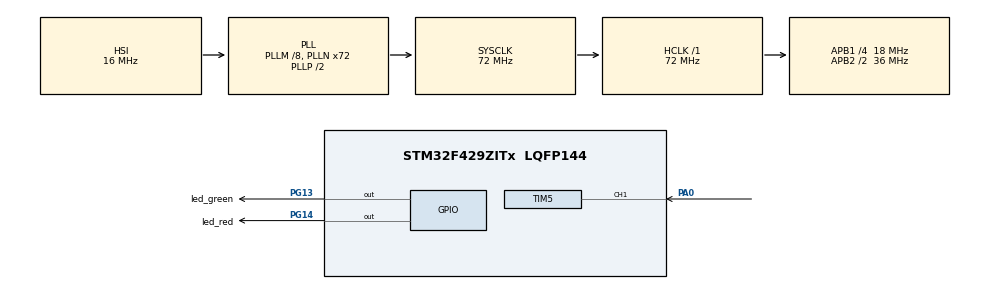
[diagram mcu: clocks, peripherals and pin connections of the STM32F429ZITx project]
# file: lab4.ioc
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Mcu.Family=STM32F4
Mcu.Name=STM32F429ZITx
Mcu.Package=LQFP144
NVIC.PriorityGroup=NVIC_PRIORITYGROUP_4
NVIC.TIM4_IRQn=true\:0\:0\:false\:true\:true\:2\:true\:true\:true
NVIC.TIM5_IRQn=true\:0\:0\:false\:true\:true\:1\:true\:true\:true
PA0/WKUP.Signal=S_TIM5_CH1
PG13.GPIO_Label=led_green
PG13.Signal=GPIO_Output
PG14.GPIO_Label=led_red
PG14.Signal=GPIO_Output
ProjectManager.HeapSize=0x200
ProjectManager.StackSize=0x400
ProjectManager.TargetToolchain=STM32CubeIDE
RCC.48MHZClocksFreq_Value=48000000
RCC.AHBFreq_Value=72000000
RCC.APB1CLKDivider=RCC_HCLK_DIV4
RCC.APB1Freq_Value=18000000
RCC.APB1TimFreq_Value=36000000
RCC.APB2CLKDivider=RCC_HCLK_DIV2
RCC.APB2Freq_Value=36000000
RCC.APB2TimFreq_Value=72000000
RCC.CortexFreq_Value=72000000
RCC.HCLKFreq_Value=72000000
RCC.HSE_VALUE=8000000
RCC.HSI_VALUE=16000000
RCC.LSE_VALUE=32768
RCC.PLLM=8
RCC.PLLN=72
RCC.PLLQ=3
RCC.PLLSAIN=50
RCC.SYSCLKFreq_VALUE=72000000
RCC.SYSCLKSource=RCC_SYSCLKSOURCE_PLLCLK
RCC.VCOOutputFreq_Value=144000000
SH.S_TIM5_CH1.0=TIM5_CH1,Input_Capture1_from_TI1
TIM4.Period=500-1
TIM4.Prescaler=36000-1
TIM5.Channel-Input_Capture1_from_TI1=TIM_CHANNEL_1
TIM5.Prescaler=3600
VP_TIM4_VS_ClockSourceINT.Mode=Internal
board=STM32F429I-DISC1

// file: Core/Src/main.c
/* USER CODE BEGIN Header */
/**
  ******************************************************************************
  * @file           : main.c
  * @brief          : Main program body
  ******************************************************************************
  * @attention
  *
  * Copyright (c) 2026 STMicroelectronics.
  * All rights reserved.
  *
  * This software is licensed under terms that can be found in the LICENSE file
  * in the root directory of this software component.
  * If no LICENSE file comes with this software, it is provided AS-IS.
  *
  ******************************************************************************
  */
/* USER CODE END Header */
#include "main.h"

TIM_HandleTypeDef htim4;
TIM_HandleTypeDef htim5;

/* USER CODE BEGIN PV */
int task = 3;
uint8_t timer_ticks = 0;

uint32_t IC_Value1 = 0;
uint32_t IC_Value2 = 0;
uint32_t Difference = 0;
float Time_Seconds = 0;
uint8_t Capture_Count = 0;
/* USER CODE END PV */

void SystemClock_Config(void);
static void MX_GPIO_Init(void);
static void MX_TIM4_Init(void);
static void MX_TIM5_Init(void);
static void MX_NVIC_Init(void);

int main(void)
{

  /* MCU Configuration--------------------------------------------------------*/

  /* Reset of all peripherals, Initializes the Flash interface and the Systick. */
  HAL_Init();

  /* Configure the system clock */
  SystemClock_Config();

  /* Initialize all configured peripherals */
  MX_GPIO_Init();
  MX_TIM4_Init();
  MX_TIM5_Init();

  /* Initialize interrupts */
  MX_NVIC_Init();
  /* USER CODE BEGIN 2 */
  HAL_TIM_Base_Start_IT(&htim4);
  HAL_TIM_IC_Start_IT(&htim5, TIM_CHANNEL_1);
  /* USER CODE END 2 */

  /* Infinite loop */
  /* USER CODE BEGIN WHILE */
  while (1)
  {
	  if (task == 2 && Capture_Count == 1) { // Jei matavimas vyksta (paspaustas pirmą kartą)
	          HAL_GPIO_WritePin(GPIOG, GPIO_PIN_13 | GPIO_PIN_14, GPIO_PIN_SET);
	          HAL_Delay(100); // Trumpas mirktelėjimas
	          HAL_GPIO_WritePin(GPIOG, GPIO_PIN_13 | GPIO_PIN_14, GPIO_PIN_RESET);
	          HAL_Delay(1900); // Likusi dalis iki 2 sekundžių
	      }
    /* USER CODE END WHILE */

  }
}

void SystemClock_Config(void)
{
  RCC_OscInitTypeDef RCC_OscInitStruct = {0};
  RCC_ClkInitTypeDef RCC_ClkInitStruct = {0};

  /** Configure the main internal regulator output voltage
  */
  __HAL_RCC_PWR_CLK_ENABLE();
  __HAL_PWR_VOLTAGESCALING_CONFIG(PWR_REGULATOR_VOLTAGE_SCALE3);

  /** Initializes the RCC Oscillators according to the specified parameters
  * in the RCC_OscInitTypeDef structure.
  */
  RCC_OscInitStruct.OscillatorType = RCC_OSCILLATORTYPE_HSI;
  RCC_OscInitStruct.HSIState = RCC_HSI_ON;
  RCC_OscInitStruct.HSICalibrationValue = RCC_HSICALIBRATION_DEFAULT;
  RCC_OscInitStruct.PLL.PLLState = RCC_PLL_ON;
  RCC_OscInitStruct.PLL.PLLSource = RCC_PLLSOURCE_HSI;
  RCC_OscInitStruct.PLL.PLLM = 8;
  RCC_OscInitStruct.PLL.PLLN = 72;
  RCC_OscInitStruct.PLL.PLLP = RCC_PLLP_DIV2;
  RCC_OscInitStruct.PLL.PLLQ = 3;
  if (HAL_RCC_OscConfig(&RCC_OscInitStruct) != HAL_OK)
  {
    Error_Handler();
  }

  /** Initializes the CPU, AHB and APB buses clocks
  */
  RCC_ClkInitStruct.ClockType = RCC_CLOCKTYPE_HCLK|RCC_CLOCKTYPE_SYSCLK
                              |RCC_CLOCKTYPE_PCLK1|RCC_CLOCKTYPE_PCLK2;
  RCC_ClkInitStruct.SYSCLKSource = RCC_SYSCLKSOURCE_PLLCLK;
  RCC_ClkInitStruct.AHBCLKDivider = RCC_SYSCLK_DIV1;
  RCC_ClkInitStruct.APB1CLKDivider = RCC_HCLK_DIV4;
  RCC_ClkInitStruct.APB2CLKDivider = RCC_HCLK_DIV2;

  if (HAL_RCC_ClockConfig(&RCC_ClkInitStruct, FLASH_LATENCY_2) != HAL_OK)
  {
    Error_Handler();
  }
}

/**
  * @brief NVIC Configuration.
  * @retval None
  */
static void MX_NVIC_Init(void)
{
  /* TIM5_IRQn interrupt configuration */
  HAL_NVIC_SetPriority(TIM5_IRQn, 0, 0);
  HAL_NVIC_EnableIRQ(TIM5_IRQn);
  /* TIM4_IRQn interrupt configuration */
  HAL_NVIC_SetPriority(TIM4_IRQn, 0, 0);
  HAL_NVIC_EnableIRQ(TIM4_IRQn);
}

static void MX_TIM4_Init(void)
{

  TIM_ClockConfigTypeDef sClockSourceConfig = {0};
  TIM_MasterConfigTypeDef sMasterConfig = {0};

  htim4.Instance = TIM4;
  htim4.Init.Prescaler = 36000-1;
  htim4.Init.CounterMode = TIM_COUNTERMODE_UP;
  htim4.Init.Period = 500-1;
  htim4.Init.ClockDivision = TIM_CLOCKDIVISION_DIV1;
  htim4.Init.AutoReloadPreload = TIM_AUTORELOAD_PRELOAD_DISABLE;
  if (HAL_TIM_Base_Init(&htim4) != HAL_OK)
  {
    Error_Handler();
  }
  sClockSourceConfig.ClockSource = TIM_CLOCKSOURCE_INTERNAL;
  if (HAL_TIM_ConfigClockSource(&htim4, &sClockSourceConfig) != HAL_OK)
  {
    Error_Handler();
  }
  sMasterConfig.MasterOutputTrigger = TIM_TRGO_RESET;
  sMasterConfig.MasterSlaveMode = TIM_MASTERSLAVEMODE_DISABLE;
  if (HAL_TIMEx_MasterConfigSynchronization(&htim4, &sMasterConfig) != HAL_OK)
  {
    Error_Handler();
  }

}

static void MX_TIM5_Init(void)
{

  TIM_MasterConfigTypeDef sMasterConfig = {0};
  TIM_IC_InitTypeDef sConfigIC = {0};

  htim5.Instance = TIM5;
  htim5.Init.Prescaler = 3600;
  htim5.Init.CounterMode = TIM_COUNTERMODE_UP;
  htim5.Init.Period = 4294967295;
  htim5.Init.ClockDivision = TIM_CLOCKDIVISION_DIV1;
  htim5.Init.AutoReloadPreload = TIM_AUTORELOAD_PRELOAD_DISABLE;
  if (HAL_TIM_IC_Init(&htim5) != HAL_OK)
  {
    Error_Handler();
  }
  sMasterConfig.MasterOutputTrigger = TIM_TRGO_RESET;
  sMasterConfig.MasterSlaveMode = TIM_MASTERSLAVEMODE_DISABLE;
  if (HAL_TIMEx_MasterConfigSynchronization(&htim5, &sMasterConfig) != HAL_OK)
  {
    Error_Handler();
  }
  sConfigIC.ICPolarity = TIM_INPUTCHANNELPOLARITY_RISING;
  sConfigIC.ICSelection = TIM_ICSELECTION_DIRECTTI;
  sConfigIC.ICPrescaler = TIM_ICPSC_DIV1;
  sConfigIC.ICFilter = 0;
  if (HAL_TIM_IC_ConfigChannel(&htim5, &sConfigIC, TIM_CHANNEL_1) != HAL_OK)
  {
    Error_Handler();
  }

}

static void MX_GPIO_Init(void)
{
  GPIO_InitTypeDef GPIO_InitStruct = {0};

  /* GPIO Ports Clock Enable */
  __HAL_RCC_GPIOA_CLK_ENABLE();
  __HAL_RCC_GPIOG_CLK_ENABLE();

  /*Configure GPIO pin Output Level */
  HAL_GPIO_WritePin(GPIOG, led_green_Pin|led_red_Pin, GPIO_PIN_RESET);

  /*Configure GPIO pins : led_green_Pin led_red_Pin */
  GPIO_InitStruct.Pin = led_green_Pin|led_red_Pin;
  GPIO_InitStruct.Mode = GPIO_MODE_OUTPUT_PP;
  GPIO_InitStruct.Pull = GPIO_NOPULL;
  GPIO_InitStruct.Speed = GPIO_SPEED_FREQ_LOW;
  HAL_GPIO_Init(GPIOG, &GPIO_InitStruct);

}

/* USER CODE BEGIN 4 */

void HAL_TIM_PeriodElapsedCallback(TIM_HandleTypeDef *htim) {
    if (task == 1 && htim->Instance == TIM4) {
        // Didiname žingsnių skaitiklį (nuo 0 iki 3, viso 4 žingsniai po 0.5s)
        timer_ticks++;
        if (timer_ticks >= 4) {
            timer_ticks = 0;
        }

        // --- PG13 VALDYMAS (Kinta kas 1 sekundę) ---
        // Kadangi pertrauktis kas 0.5s, būseną keičiame kas antrą pertrauktį
        if (timer_ticks % 2 == 0) {
            HAL_GPIO_TogglePin(GPIOG, GPIO_PIN_13);
        }

        // --- PG14 VALDYMAS (2s periodas: 1.5s ON, 0.5s OFF) ---
        // Žingsniai: 0 (0.5s), 1 (1.0s), 2 (1.5s) -> ON; 3 (2.0s) -> OFF
        if (timer_ticks < 3) {
            HAL_GPIO_WritePin(GPIOG, GPIO_PIN_14, GPIO_PIN_SET);   // Įjungtas
        } else {
            HAL_GPIO_WritePin(GPIOG, GPIO_PIN_14, GPIO_PIN_RESET); // Išjungtas
        }
    }
}

void HAL_TIM_IC_CaptureCallback(TIM_HandleTypeDef *htim) {
    if (task==2 && htim->Instance == TIM5) {
        if (Capture_Count == 0) { // Pirmas paspaudimas
            IC_Value1 = HAL_TIM_ReadCapturedValue(htim, TIM_CHANNEL_1);
            Capture_Count = 1;

            // Išjungiame visus LED prieš naują matavimą
            HAL_GPIO_WritePin(GPIOG, GPIO_PIN_13 | GPIO_PIN_14, GPIO_PIN_RESET);

        } else if (Capture_Count == 1) { // Antras paspaudimas
            IC_Value2 = HAL_TIM_ReadCapturedValue(htim, TIM_CHANNEL_1);

            // Skaičiuojame skirtumą (įvertinant galimą laikmačio persipildymą)
            if (IC_Value2 > IC_Value1) {
                Difference = IC_Value2 - IC_Value1;
            } else {
                Difference = (0xFFFFFFFF - IC_Value1) + IC_Value2;
            }

            // Paverčiame į sekundes (jei dažnis 10kHz, dalijame iš 10000)
            Time_Seconds = (float)Difference / 10000.0f;

            // REZULTATO INDIKACIJA pagal lentelę (pavyzdys):
            if (Time_Seconds > 0 && Time_Seconds <= 2.0) {
                HAL_GPIO_WritePin(GPIOG, GPIO_PIN_13, GPIO_PIN_SET); // Pvz. tik vienas LED
            } else if (Time_Seconds > 2.0 && Time_Seconds <= 4.0) {
                HAL_GPIO_WritePin(GPIOG, GPIO_PIN_14, GPIO_PIN_SET); // Pvz. kitas LED
            } else if (Time_Seconds > 4.0 && Time_Seconds <= 6.0) {
                HAL_GPIO_WritePin(GPIOG, GPIO_PIN_13 | GPIO_PIN_14, GPIO_PIN_SET); // Abu LED
            }

            Capture_Count = 0; // Ruošiamės naujam matavimui
        }
    }
}
/* USER CODE END 4 */

void Error_Handler(void)
{
  __disable_irq();
  while (1)
  {
  }
}
